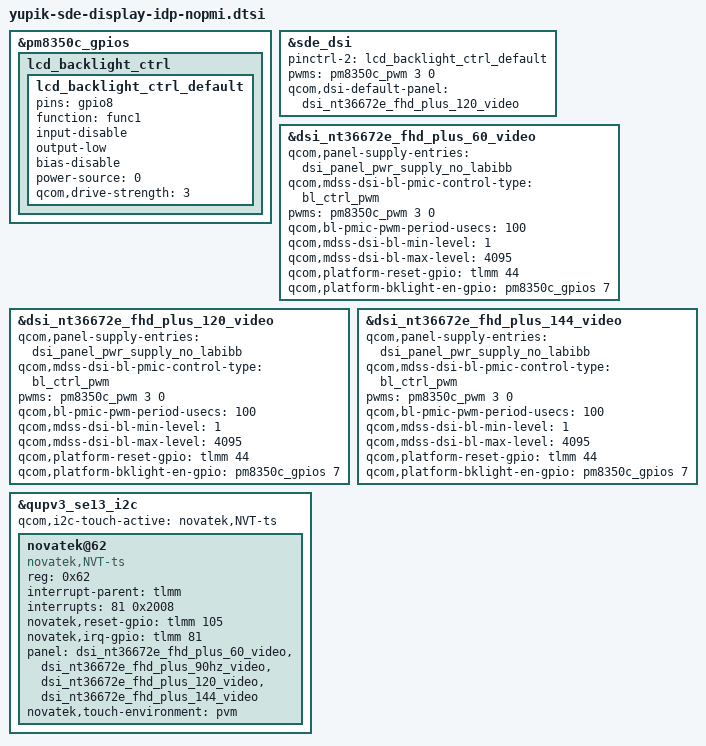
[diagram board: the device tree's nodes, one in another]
// SPDX-License-Identifier: BSD-3-Clause
/*
 * Copyright (c) Qualcomm Technologies, Inc. and/or its subsidiaries.
 */

#include "yupik-sde-display.dtsi"

&pm8350c_gpios {
	lcd_backlight_ctrl {
		lcd_backlight_ctrl_default: lcd_backlight_ctrl_default {
			pins = "gpio8";
			function = "func1";
			input-disable;
			output-low;
			bias-disable;
			power-source = <0>;
			qcom,drive-strength = <3>;
		};
	};
};

&sde_dsi {
	/delete-property/ lab-supply;
	/delete-property/ ibb-supply;

	pinctrl-names = "panel_active", "panel_suspend", "pwm_pin";
	pinctrl-2 = <&lcd_backlight_ctrl_default>;
	pwms = <&pm8350c_pwm 3 0>;
	qcom,dsi-default-panel = <&dsi_nt36672e_fhd_plus_120_video>;
};

&dsi_nt36672e_fhd_plus_60_video {
	qcom,panel-supply-entries = <&dsi_panel_pwr_supply_no_labibb>;
	qcom,mdss-dsi-bl-pmic-control-type = "bl_ctrl_pwm";
	pwms = <&pm8350c_pwm 3 0>;
	qcom,bl-pmic-pwm-period-usecs = <100>;
	qcom,mdss-dsi-bl-min-level = <1>;
	qcom,mdss-dsi-bl-max-level = <4095>;
	qcom,platform-reset-gpio = <&tlmm 44 0>;
	qcom,platform-bklight-en-gpio = <&pm8350c_gpios 7 0>;
};

&dsi_nt36672e_fhd_plus_120_video {
	qcom,panel-supply-entries = <&dsi_panel_pwr_supply_no_labibb>;
	qcom,mdss-dsi-bl-pmic-control-type = "bl_ctrl_pwm";
	pwms = <&pm8350c_pwm 3 0>;
	qcom,bl-pmic-pwm-period-usecs = <100>;
	qcom,mdss-dsi-bl-min-level = <1>;
	qcom,mdss-dsi-bl-max-level = <4095>;
	qcom,platform-reset-gpio = <&tlmm 44 0>;
	qcom,platform-bklight-en-gpio = <&pm8350c_gpios 7 0>;
};

&dsi_nt36672e_fhd_plus_144_video {
	qcom,panel-supply-entries = <&dsi_panel_pwr_supply_no_labibb>;
	qcom,mdss-dsi-bl-pmic-control-type = "bl_ctrl_pwm";
	pwms = <&pm8350c_pwm 3 0>;
	qcom,bl-pmic-pwm-period-usecs = <100>;
	qcom,mdss-dsi-bl-min-level = <1>;
	qcom,mdss-dsi-bl-max-level = <4095>;
	qcom,platform-reset-gpio = <&tlmm 44 0>;
	qcom,platform-bklight-en-gpio = <&pm8350c_gpios 7 0>;
};

&qupv3_se13_i2c{
	status = "ok";
	qcom,i2c-touch-active="novatek,NVT-ts";

	novatek@62 {
		compatible = "novatek,NVT-ts";
		reg = <0x62>;
		interrupt-parent = <&tlmm>;
		interrupts = <81 0x2008>;
		novatek,reset-gpio = <&tlmm 105 0x00>;
		novatek,irq-gpio = <&tlmm 81 0x2008>;

		panel = <&dsi_nt36672e_fhd_plus_60_video
			&dsi_nt36672e_fhd_plus_90hz_video
			&dsi_nt36672e_fhd_plus_120_video
			&dsi_nt36672e_fhd_plus_144_video>;

		novatek,touch-environment = "pvm";
	};
};
